# CH32L103 register map
Vendor: WCH Ltd.; File version: 1.0
Registers are 32-bit, read-write, reset 0x0 unless marked. A register's access mark holds for its fields unless they carry their own. Offsets are from the block's base; [hi:lo] are bit positions; {n}, {i} and the like mark numbered series; 'fields as' and 'values as' point back to an identical list.

## USBFS — USB full speed host/equipment control register
Base 0x50000000
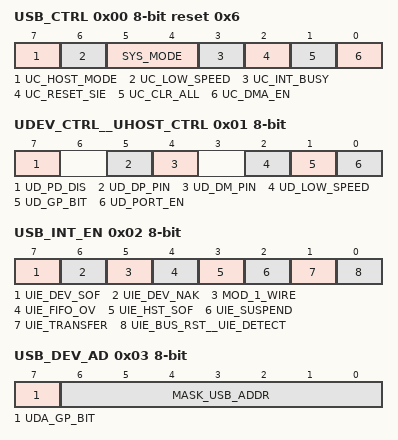
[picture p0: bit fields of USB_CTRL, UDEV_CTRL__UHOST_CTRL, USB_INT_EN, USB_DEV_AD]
0x00 USB_CTRL 8-bit reset 0x6 — USB base control
  [7] UC_HOST_MODE — enable USB host mode: 0=device mode, 1=host mode
  [6] UC_LOW_SPEED — USB bus signal transmission rate select bit
  [5:4] SYS_MODE — Test mode in Host mode
  [3] UC_INT_BUSY — enable automatic responding busy for device mode or automatic pause for host mode during interrupt flag UIF_TRANSFER valid
  [2] UC_RESET_SIE — force reset USB SIE, need software clear
  [1] UC_CLR_ALL — force clear FIFO and count of USB
  [0] UC_DMA_EN — DMA enable and DMA interrupt enable for USB
0x01 UDEV_CTRL__UHOST_CTRL 8-bit — USB host physical port control register;USB host physical port control register
  [7] UD_PD_DIS — USB host port internal pull-down resistance control
  [5] UD_DP_PIN — current pin status
  [4] UD_DM_PIN — current pin status
  [2] UD_LOW_SPEED — usb host port low-speed mode enable
  [1] UD_GP_BIT — common flag bit
  [0] UD_PORT_EN — usb host port enable
0x02 USB_INT_EN 8-bit — USB interrupt enable
  [7] UIE_DEV_SOF — enable interrupt for SOF responded for USB device mode
  [6] UIE_DEV_NAK — enable interrupt for NAK responded for USB device mode
  [5] MOD_1_WIRE — USB single-line mode enable
  [4] UIE_FIFO_OV — enable interrupt for FIFO overflow
  [3] UIE_HST_SOF — in USB host mode, SOF is interrupt periodically
  [2] UIE_SUSPEND — enable interrupt for USB suspend or resume event
  [1] UIE_TRANSFER — enable interrupt for USB transfer completion
  [0] UIE_BUS_RST__UIE_DETECT — enable interrupt for USB bus reset event for USB device mode;enable interrupt for USB device detected event for USB host mode
0x03 USB_DEV_AD 8-bit — USB device address
  [7] UDA_GP_BIT — general purpose bit
  [6:0] MASK_USB_ADDR — bit mask for USB device address
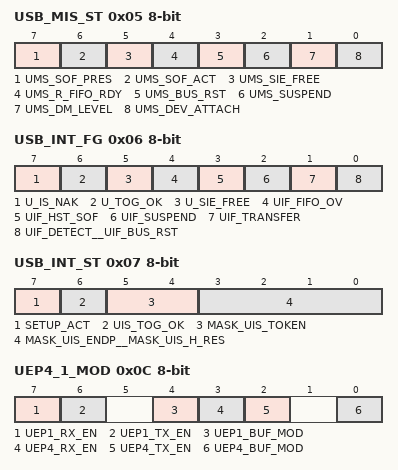
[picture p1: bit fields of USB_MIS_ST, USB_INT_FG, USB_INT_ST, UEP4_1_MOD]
0x05 USB_MIS_ST 8-bit — USB miscellaneous status register
  [7] UMS_SOF_PRES — SOF package indicates the status bit in USB host mode
  [6] UMS_SOF_ACT — SOF package transmission status bit in USB host mode
  [5] UMS_SIE_FREE — IDLE state bit of the USB protocol processor
  [4] UMS_R_FIFO_RDY — USB receives FIFO dataready status bit
  [3] UMS_BUS_RST — USB bus reset status bit
  [2] UMS_SUSPEND — USB hangs up status bits
  [1] UMS_DM_LEVEL — judgment speed
  [0] UMS_DEV_ATTACH — port connection status
0x06 USB_INT_FG 8-bit — USB miscellaneous status register
  [7] U_IS_NAK — SOF package indicates the status bit in USB host mode
  [6] U_TOG_OK — synchronization flag matches the status bits
  [5] U_SIE_FREE — PID characteristic
  [4] UIF_FIFO_OV — USB FIFO overflow interrupt flag
  [3] UIF_HST_SOF — SOF timer interrupt flag in USB host mode
  [2] UIF_SUSPEND — USB bus suspend or wake-up event interrupt flag
  [1] UIF_TRANSFER — USB transfer completion interrupt flag
  [0] UIF_DETECT__UIF_BUS_RST — interrupt flag bit
0x07 USB_INT_ST 8-bit ro — USB interrupt status register
  [7] SETUP_ACT — SETUP transaction is completed
  [6] UIS_TOG_OK — Match Status Bits
  [5:4] MASK_UIS_TOKEN — In device mode, the token PID identifier of the current USB transfer transaction
  [3:0] MASK_UIS_ENDP__MASK_UIS_H_RES — device mode:the endpoint number of current USB transfer transaction ; host mode :PID identifier of the current USB transfer transaction
0x08 USB_RX_LEN 16-bit ro — USB miscellaneous status register
  [9:0] USB_RX_LEN — current number of data bytes received by the USB endpoint
0x0C UEP4_1_MOD 8-bit — endpoint 4/1 mode
  [7] UEP1_RX_EN — enable USB endpoint 1 receiving (OUT)
  [6] UEP1_TX_EN — enable USB endpoint 1 transmittal (IN)
  [4] UEP1_BUF_MOD — buffer mode of USB endpoint 1
  [3] UEP4_RX_EN — enable USB endpoint 4 receiving (OUT)
  [2] UEP4_TX_EN — enable USB endpoint 4 transmittal (IN)
  [0] UEP4_BUF_MOD — buffer mode of USB endpoint 4
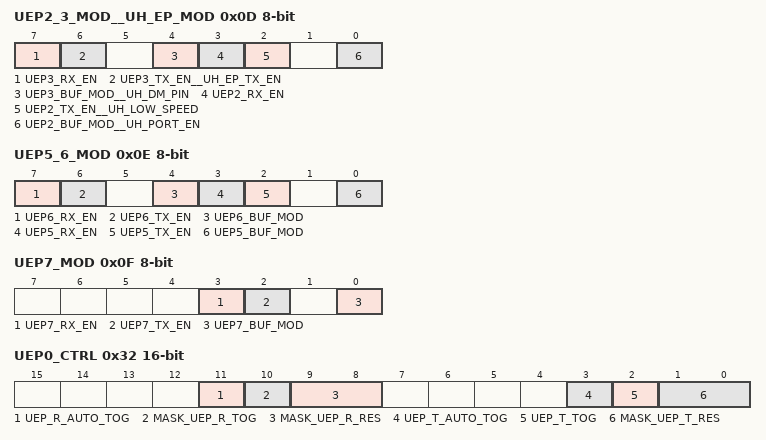
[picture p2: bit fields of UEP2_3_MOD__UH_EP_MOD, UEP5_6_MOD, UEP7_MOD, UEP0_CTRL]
0x0D UEP2_3_MOD__UH_EP_MOD 8-bit — endpoint 2/3 mode;USB host endpoint mode control register
  [7] UEP3_RX_EN — enable USB endpoint 3 receiving (OUT)
  [6] UEP3_TX_EN__UH_EP_TX_EN — enable USB endpoint 3 transmittal (IN);endpoint send enable
  [4] UEP3_BUF_MOD__UH_DM_PIN — buffer mode of USB endpoint 3;endpoint send the data buffer mode control
  [3] UEP2_RX_EN — enable USB endpoint 2 receiving (OUT)
  [2] UEP2_TX_EN__UH_LOW_SPEED — enable USB endpoint 2 transmittal (IN);host endpoint receive enable
  [0] UEP2_BUF_MOD__UH_PORT_EN — buffer mode of USB endpoint 2;endpoint receive the data buffer mode control
0x0E UEP5_6_MOD 8-bit — endpoint 5/6 mode
  [7] UEP6_RX_EN — enable USB endpoint 6 receiving (OUT)
  [6] UEP6_TX_EN — enable USB endpoint 6 transmittal (IN)
  [4] UEP6_BUF_MOD — buffer mode of USB endpoint 6
  [3] UEP5_RX_EN — enable USB endpoint 5 receiving (OUT)
  [2] UEP5_TX_EN — enable USB endpoint 5 transmittal (IN)
  [0] UEP5_BUF_MOD — buffer mode of USB endpoint 5
0x0F UEP7_MOD 8-bit — endpoint 7 mode
  [3] UEP7_RX_EN — enable USB endpoint 7 receiving (OUT)
  [2] UEP7_TX_EN — enable USB endpoint 7 transmittal (IN)
  [0] UEP7_BUF_MOD — buffer mode of USB endpoint 7
0x10 UEP0_DMA — endpoint 0 DMA buffer address
  [14:0] UEP0_DMA — endpoint buffer start address
0x14 UEP1_DMA — endpoint 1 DMA buffer address
  [14:0] UEP1_DMA — endpoint buffer start address
0x18 UEP2_DMA__UH_RX_DMA — endpoint 2 DMA buffer address
  [15:0] UEP2_DMA__UH_RX_DMA — endpoint buffer start address
0x1C UEP3_DMA__UH_TX_DMA — endpoint 3 DMA buffer address
  [15:0] UEP3_DMA__UH_TX_DMA — endpoint buffer start address
{0x10+4i} UEP{i}_DMA (i=4..7) — endpoint {i} DMA buffer address
  [14:0] UEP{i}_DMA — endpoint buffer start address
0x30 UEP0_T_LEN 16-bit — endpoint send length register
  [6:0] UEP0_T_LEN — set USB endpoint send data bytes
0x32 UEP0_CTRL 16-bit — endpoint control register
  [11] UEP_R_AUTO_TOG — sync trigger bit aoto flip enable control
  [10] MASK_UEP_R_TOG — desired synchronization trigger bit for receiver of USB endpoint (handling OUT transactions)
  [9:8] MASK_UEP_R_RES — response control of endpoint's receiver to the OUT transaction
  [3] UEP_T_AUTO_TOG — sync trigger bit aoto flip enable control
  [2] UEP_T_TOG — synchronization trigger bit for sender of USB endpoint (handling IN transactions)
  [1:0] MASK_UEP_T_RES — response control of endpoint's receiver to the IN transaction
0x34 UEP1_T_LEN 16-bit — endpoint send length register
  [6:0] UEP1_T_LEN — set USB endpoint send data bytes
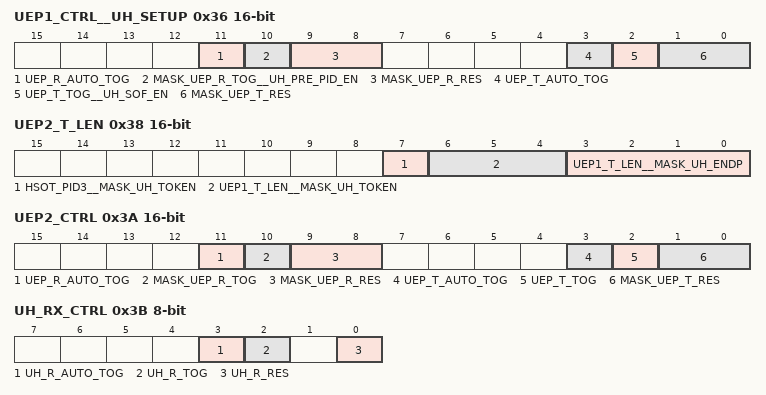
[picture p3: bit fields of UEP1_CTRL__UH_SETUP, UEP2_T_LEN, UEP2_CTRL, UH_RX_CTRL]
0x36 UEP1_CTRL__UH_SETUP 16-bit — endpoint control register
  [11] UEP_R_AUTO_TOG — sync trigger bit aoto flip enable control
  [10] MASK_UEP_R_TOG__UH_PRE_PID_EN — desired synchronization trigger bit for receiver of USB endpoint (handling OUT transactions);low-speed lead packet PRE PID enable
  [9:8] MASK_UEP_R_RES — response control of endpoint's receiver to the OUT transaction
  [3] UEP_T_AUTO_TOG — sync trigger bit aoto flip enable control
  [2] UEP_T_TOG__UH_SOF_EN — synchronization trigger bit for sender of USB endpoint (handling IN transactions);aoto generate SOF packet enable
  [1:0] MASK_UEP_T_RES — response control of endpoint's receiver to the IN transaction
0x38 UEP2_T_LEN 16-bit — endpoint send length register
  [7] HSOT_PID3__MASK_UH_TOKEN — PID[3] in host mode;set the token PID packet flag
  [6:4] UEP1_T_LEN__MASK_UH_TOKEN — set USB endpoint send data bytes;set the token PID packet flag
  [3:0] UEP1_T_LEN__MASK_UH_ENDP — set the endpoint number of the target device; set USB endpoint send data bytes
0x3A UEP2_CTRL 16-bit — endpoint control register
  fields as UEP0_CTRL
0x3B UH_RX_CTRL 8-bit — USB host receive endpoint control register
  [3] UH_R_AUTO_TOG — sync trigger bit aoto flip enable control
  [2] UH_R_TOG — sync trigger bit expected by usb host receiver
  [0] UH_R_RES — host receiver response control for IN transactions
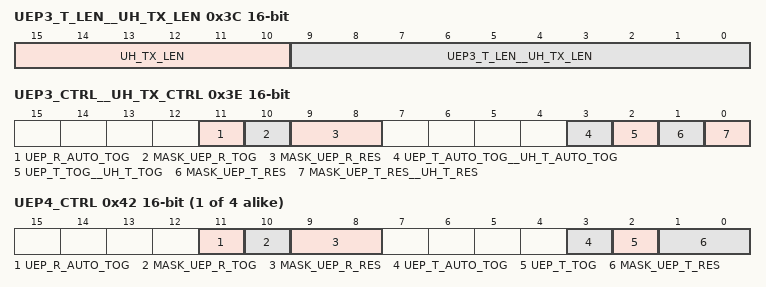
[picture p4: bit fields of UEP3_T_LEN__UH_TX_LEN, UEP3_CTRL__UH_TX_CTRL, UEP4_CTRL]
0x3C UEP3_T_LEN__UH_TX_LEN 16-bit — endpoint send length register
  [15:10] UH_TX_LEN — set USB endpoint send data bytes
  [9:0] UEP3_T_LEN__UH_TX_LEN — set USB endpoint send data bytes
0x3E UEP3_CTRL__UH_TX_CTRL 16-bit — endpoint control register;USB host send endpoint control register
  [11] UEP_R_AUTO_TOG — sync trigger bit aoto flip enable control
  [10] MASK_UEP_R_TOG — desired synchronization trigger bit for receiver of USB endpoint (handling OUT transactions)
  [9:8] MASK_UEP_R_RES — response control of endpoint's receiver to the OUT transaction
  [3] UEP_T_AUTO_TOG__UH_T_AUTO_TOG — sync trigger bit aoto flip enable control
  [2] UEP_T_TOG__UH_T_TOG — synchronization trigger bit for sender of USB endpoint (handling IN transactions)
  [1] MASK_UEP_T_RES — response control of endpoint's receiver to the IN transaction
  [0] MASK_UEP_T_RES__UH_T_RES — response control of endpoint's receiver to the IN transaction; host send response control for OUT/SETUP transactions
{0x30+4i} UEP{i}_T_LEN 16-bit (i=4..7) — endpoint send length register
  [6:0] UEP{i}_T_LEN — set USB endpoint send data bytes
{0x32+4i} UEP{i}_CTRL 16-bit (i=4..7) — endpoint control register
  fields as UEP0_CTRL
